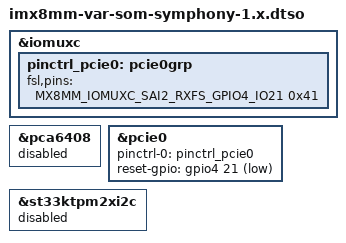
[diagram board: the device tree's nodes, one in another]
// SPDX-License-Identifier: (GPL-2.0+ OR MIT)
/*
 * Device tree overlay to support the VAR-SOM-MX8M-MINI on Symphony Board 1.x
 *
 * Copyright 2025 Variscite Ltd.
 */

/dts-v1/;
/plugin/;

#include <dt-bindings/gpio/gpio.h>
#include "imx8mm-pinfunc.h"

&iomuxc {
	pinctrl_pcie0: pcie0grp {
		fsl,pins = <
			MX8MM_IOMUXC_SAI2_RXFS_GPIO4_IO21		0x41
		>;
	};
};

&pca6408 {
	status = "disabled";
};

&pcie0 {
	pinctrl-names = "default";
	pinctrl-0 = <&pinctrl_pcie0>;
	reset-gpio = <&gpio4 21 GPIO_ACTIVE_LOW>;
};

&st33ktpm2xi2c {
	status = "disabled";
};
